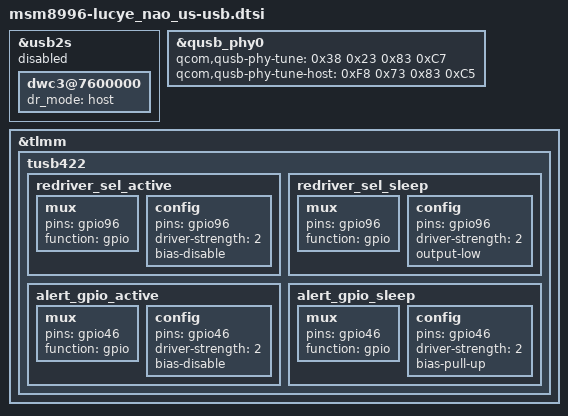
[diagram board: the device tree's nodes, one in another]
/* Copyright (c) 2015, The Linux Foundation. All rights reserved.
 *
 * This program is free software; you can redistribute it and/or modify
 * it under the terms of the GNU General Public License version 2 and
 * only version 2 as published by the Free Software Foundation.
 *
 * This program is distributed in the hope that it will be useful,
 * but WITHOUT ANY WARRANTY; without even the implied warranty of
 * MERCHANTABILITY or FITNESS FOR A PARTICULAR PURPOSE.  See the
 * GNU General Public License for more details.
 */

#include "../msm8996-usb-typec-tusb422.dtsi"

&usb2s {
	status = "disabled";

	dwc3@7600000 {
		dr_mode = "host";
	};
};

&qusb_phy0 {
	qcom,qusb-phy-tune = <0x38 0x23 0x83 0xC7>;
	qcom,qusb-phy-tune-host = <0xF8 0x73 0x83 0xC5>;
};

&tlmm {
  tusb422 {
    /* GPIO_96 : USB_REDRIVER */
    redriver_sel_active: redriver_sel_active {
      mux {
        pins = "gpio96";
        function = "gpio";
      };

      config {
        pins = "gpio96";
        driver-strength = <2>;
        bias-disable;		/* NO PULL */
      };
    };

    redriver_sel_sleep: redriver_sel_sleep {
      mux {
        pins = "gpio96";
        function = "gpio";
      };

      config {
        pins = "gpio96";
        driver-strength = <2>;
        output-low;		/* Output Low */
      };
    };

    /* GPIO_46 : USB_ALERT */
    alert_gpio_active: alert_gpio_active {
      mux {
        pins = "gpio46";
        function = "gpio";
      };

      config {
        pins = "gpio46";
        driver-strength = <2>;
        bias-disable;
      };
    };

    alert_gpio_sleep: alert_gpio_sleep {
      mux {
        pins = "gpio46";
        function = "gpio";
      };

      config {
        pins = "gpio46";
        driver-strength = <2>;
        bias-pull-up;
      };
    };
  };
};
